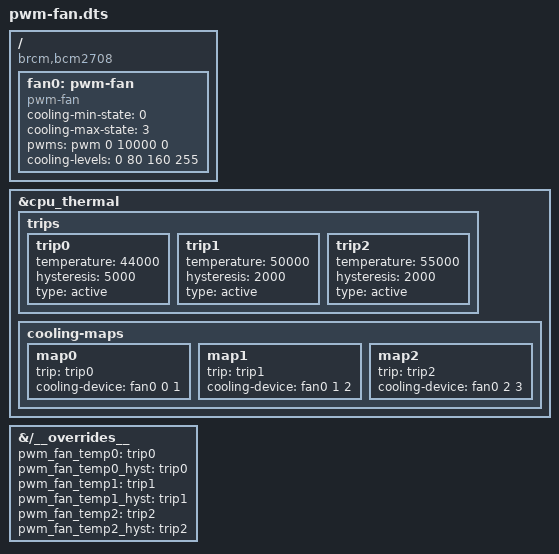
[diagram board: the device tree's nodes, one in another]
/*
 * Overlay for the Raspberry Pi GPIO Fan @ BCM GPIO12.
 * sudo dtc -W no-unit_address_vs_reg -@ -I dts -O dtb -o /boot/overlays/pwm-fan.dtbo pwm-fan.dts
 */
/dts-v1/;
/plugin/;

/ {
	compatible = "brcm,bcm2708";

	fragment@0 {
		target-path = "/";
		__overlay__ {
			fan0: pwm-fan {
				compatible = "pwm-fan";
				cooling-min-state = <0>;
				cooling-max-state = <3>;
				#cooling-cells = <2>;
				pwms = <&pwm 0 10000 0>;
				cooling-levels = <0 80 160 255>;
			};
		};
	};

	fragment@1 {
		target = <&cpu_thermal>;
		__overlay__ {
			trips {
				trip0: trip0 {
					temperature = <44000>;
					hysteresis = <5000>;
					type = "active";
				};
				trip1: trip1 {
					temperature = <50000>;
					hysteresis = <2000>;
					type = "active";
				};
				trip2: trip2 {
					temperature = <55000>;
					hysteresis = <2000>;
					type = "active";
				};
			};
			cooling-maps {
				map0 {
					trip = <&trip0>;
					cooling-device = <&fan0 0 1>;
				};
				map1 {
					trip = <&trip1>;
					cooling-device = <&fan0 1 2>;
				};
				map2 {
					trip = <&trip2>;
					cooling-device = <&fan0 2 3>;
				};
			};
		};
	};

	fragment@2 {
		target-path = "/__overrides__";
		__overlay__ {
			pwm_fan_temp0 =		<&trip0>,"temperature:0";
			pwm_fan_temp0_hyst =	<&trip0>,"hysteresis:0";
			pwm_fan_temp1 =		<&trip1>,"temperature:0";
			pwm_fan_temp1_hyst =	<&trip1>,"hysteresis:0";
			pwm_fan_temp2 =		<&trip2>,"temperature:0";
			pwm_fan_temp2_hyst =	<&trip2>,"hysteresis:0";
		};
	};
};
